AUTOSAR XML (schema 4-0-3)
package /MICROSAR/Det_swc/Interfaces
  client server interface DETService: is-service=true, service-kind=DEVELOPMENT-ERROR-TRACER
    operation ReportError: possible-error=E_OK
      arg InstanceId: type=uint8, direction=IN
      arg ApiId: type=uint8, direction=IN
      arg ErrorId: type=uint8, direction=IN
    error E_OK: error-code=0
package /MICROSAR/Det_swc/ComponentTypes
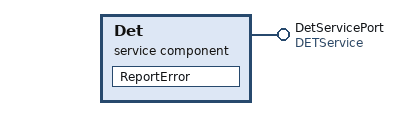
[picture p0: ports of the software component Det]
  service sw component type Det: category=SERVICE_COMPONENT
    provide port DetServicePort: provided-interface=DETService
    behavior DetInternalBehavior: handle-termination-and-restart=NO-SUPPORT, port-api-option{enable-take-address=true, indirect-api=false, port-defined-argument-value{value=4096, value-type=uint16}, port=DetServicePort}
      operation invoked event OpEventReportError_ReportError_DetServicePort: start-on-event=ReportError, operation=DetServicePort.ReportError
      runnable ReportError: can-be-invoked-concurrently=true, symbol=Det_ReportError
  swc implementation DetImplementation: programming-language=C, behavior=DetInternalBehavior
